AUTOSAR XML (schema 4-0-3)
standard types defined: UInt32, UInt8
package /AUTOSAR_Platform/DataConstrs
  range DC_UInt8: raw 0..255
package /PATAC/MSM/ComponentTypes
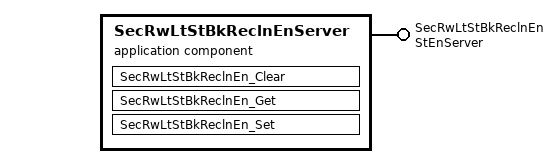
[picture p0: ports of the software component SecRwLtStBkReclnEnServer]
  application sw component type SecRwLtStBkReclnEnServer
    provide port SecRwLtStBkReclnEn: provided-com-specs=[{operation=Clear, queue-length=1}, {operation=Get, queue-length=1}, {operation=Set, queue-length=1}], provided-interface=StEnServer
    behavior SecRwLtStBkReclnEnServer_InternalBehavior
      operation invoked event OIT_SecRwLtStBkReclnEn_Clear_SecRwLtStBkReclnEn_Clear: start-on-event=SecRwLtStBkReclnEn_Clear, operation=SecRwLtStBkReclnEn.Clear
      operation invoked event OIT_SecRwLtStBkReclnEn_Get_SecRwLtStBkReclnEn_Get: start-on-event=SecRwLtStBkReclnEn_Get, operation=SecRwLtStBkReclnEn.Get
      operation invoked event OIT_SecRwLtStBkReclnEn_Set_SecRwLtStBkReclnEn_Set: start-on-event=SecRwLtStBkReclnEn_Set, operation=SecRwLtStBkReclnEn.Set
      runnable SecRwLtStBkReclnEn_Clear
      runnable SecRwLtStBkReclnEn_Get
      runnable SecRwLtStBkReclnEn_Set
  swc implementation SecRwLtStBkReclnEnServer_Implementation: behavior=SecRwLtStBkReclnEnServer_InternalBehavior
    code-descriptors:
      code Default: artifact-descriptors=autosar-engineering-object={short-label=Default, category=SWSRC}
package /PATAC/MSM/ModeAdjust/PortInterface
  client server interface StEnServer
    operation Clear
      arg data: type=UInt8, direction=IN, server-argument-impl-policy=USE-ARGUMENT-TYPE
    operation Get
      arg data: type=UInt32, direction=OUT, server-argument-impl-policy=USE-ARGUMENT-TYPE
    operation Set
      arg data: type=UInt8, direction=IN, server-argument-impl-policy=USE-ARGUMENT-TYPE
